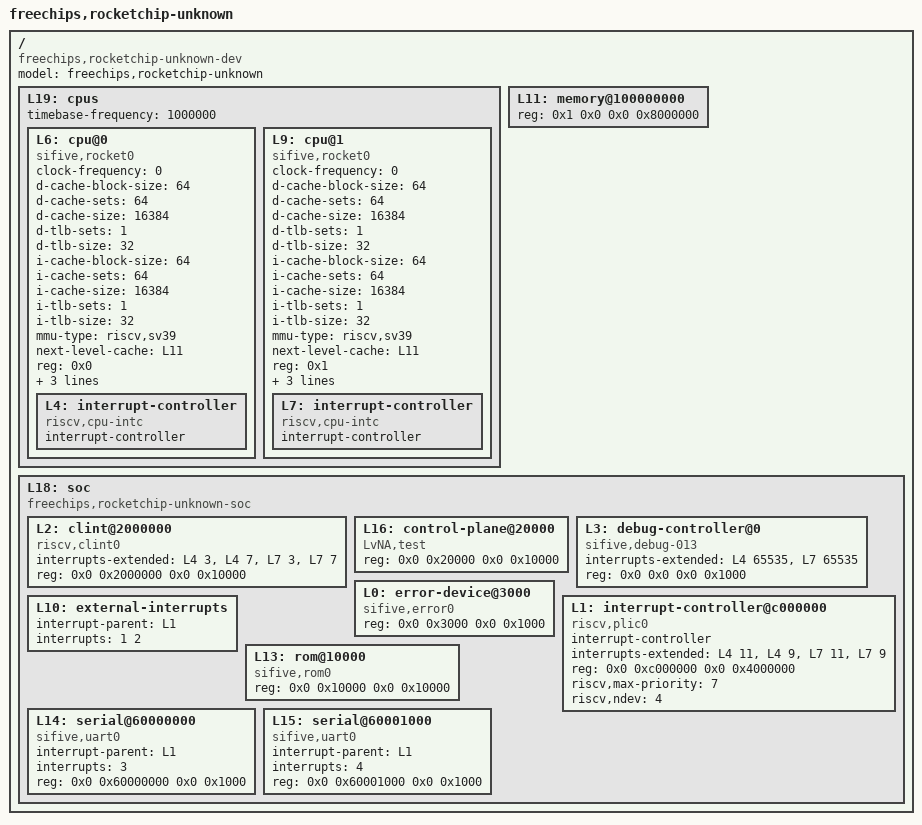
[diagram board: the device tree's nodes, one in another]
/dts-v1/;

/ {
	#address-cells = <2>;
	#size-cells = <2>;
	compatible = "freechips,rocketchip-unknown-dev";
	model = "freechips,rocketchip-unknown";
	L19: cpus {
		#address-cells = <1>;
		#size-cells = <0>;
		timebase-frequency = <1000000>;
		L6: cpu@0 {
			clock-frequency = <0>;
			compatible = "sifive,rocket0", "riscv";
			d-cache-block-size = <64>;
			d-cache-sets = <64>;
			d-cache-size = <16384>;
			d-tlb-sets = <1>;
			d-tlb-size = <32>;
			device_type = "cpu";
			i-cache-block-size = <64>;
			i-cache-sets = <64>;
			i-cache-size = <16384>;
			i-tlb-sets = <1>;
			i-tlb-size = <32>;
			mmu-type = "riscv,sv39";
			next-level-cache = <&L11>;
			reg = <0x0>;
			riscv,isa = "rv64imac";
			status = "okay";
			timebase-frequency = <1000000>;
			tlb-split;
			L4: interrupt-controller {
				#interrupt-cells = <1>;
				compatible = "riscv,cpu-intc";
				interrupt-controller;
			};
		};
		L9: cpu@1 {
			clock-frequency = <0>;
			compatible = "sifive,rocket0", "riscv";
			d-cache-block-size = <64>;
			d-cache-sets = <64>;
			d-cache-size = <16384>;
			d-tlb-sets = <1>;
			d-tlb-size = <32>;
			device_type = "cpu";
			i-cache-block-size = <64>;
			i-cache-sets = <64>;
			i-cache-size = <16384>;
			i-tlb-sets = <1>;
			i-tlb-size = <32>;
			mmu-type = "riscv,sv39";
			next-level-cache = <&L11>;
			reg = <0x1>;
			riscv,isa = "rv64imac";
			status = "okay";
			timebase-frequency = <1000000>;
			tlb-split;
			L7: interrupt-controller {
				#interrupt-cells = <1>;
				compatible = "riscv,cpu-intc";
				interrupt-controller;
			};
		};
	};
	L11: memory@100000000 {
		device_type = "memory";
		reg = <0x1 0x0 0x0 0x8000000>;
	};
	L18: soc {
		#address-cells = <2>;
		#size-cells = <2>;
		compatible = "freechips,rocketchip-unknown-soc", "simple-bus";
		ranges;
		L2: clint@2000000 {
			compatible = "riscv,clint0";
			interrupts-extended = <&L4 3 &L4 7 &L7 3 &L7 7>;
			reg = <0x0 0x2000000 0x0 0x10000>;
			reg-names = "control";
		};
		L16: control-plane@20000 {
			compatible = "LvNA,test", "LvNA,test";
			reg = <0x0 0x20000 0x0 0x10000>;
			reg-names = "control";
		};
		L3: debug-controller@0 {
			compatible = "sifive,debug-013", "riscv,debug-013";
			interrupts-extended = <&L4 65535 &L7 65535>;
			reg = <0x0 0x0 0x0 0x1000>;
			reg-names = "control";
		};
		L0: error-device@3000 {
			compatible = "sifive,error0";
			reg = <0x0 0x3000 0x0 0x1000>;
		};
		L10: external-interrupts {
			interrupt-parent = <&L1>;
			interrupts = <1 2>;
		};
		L1: interrupt-controller@c000000 {
			#interrupt-cells = <1>;
			compatible = "riscv,plic0";
			interrupt-controller;
			interrupts-extended = <&L4 11 &L4 9 &L7 11 &L7 9>;
			reg = <0x0 0xc000000 0x0 0x4000000>;
			reg-names = "control";
			riscv,max-priority = <7>;
			riscv,ndev = <4>;
		};
		L13: rom@10000 {
			compatible = "sifive,rom0";
			reg = <0x0 0x10000 0x0 0x10000>;
			reg-names = "mem";
		};
		L14: serial@60000000 {
			compatible = "sifive,uart0";
			interrupt-parent = <&L1>;
			interrupts = <3>;
			reg = <0x0 0x60000000 0x0 0x1000>;
			reg-names = "control";
		};
		L15: serial@60001000 {
			compatible = "sifive,uart0";
			interrupt-parent = <&L1>;
			interrupts = <4>;
			reg = <0x0 0x60001000 0x0 0x1000>;
			reg-names = "control";
		};
	};
};
